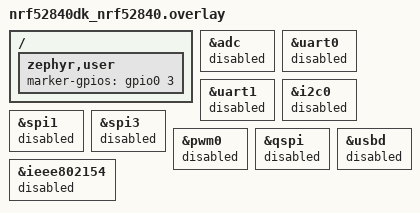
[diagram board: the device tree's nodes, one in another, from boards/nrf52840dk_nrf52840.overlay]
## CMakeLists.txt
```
cmake_minimum_required(VERSION 3.20.0)
find_package(Zephyr REQUIRED HINTS $ENV{ZEPHYR_BASE})
project(low_power_zephyr_comparison)

target_sources(app PRIVATE
    src/main.c
    ../common/src/scenario.c
)
target_include_directories(app PRIVATE ../common/include)

target_compile_definitions(app PRIVATE
    SCENARIO_PERIOD_MS=${CONFIG_SCENARIO_PERIOD_MS}
    SCENARIO_PULSE_MS=${CONFIG_SCENARIO_PULSE_MS}
    SCENARIO_WORKLOAD_ITERATIONS=${CONFIG_SCENARIO_WORKLOAD_ITERATIONS}
)
```

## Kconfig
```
mainmenu "Low-Power nRF52 Comparison"

config SCENARIO_LED
    bool "Use the on-board LED as a 50 ms activity indicator"
    default y
    help
      The on-board LED adds a noticeable load to current measurements.
      Disable it for an MCU-focused low-power baseline. Keep the same
      setting in both the bare-metal and Zephyr builds.

config SCENARIO_PERIOD_MS
    int "Periodic wake-up interval in milliseconds"
    range 100 600000
    default 5000
    help
      Period between application wake-up events.

config SCENARIO_PULSE_MS
    int "LED pulse duration in milliseconds"
    range 1 999
    default 50
    help
      LED on-time. Must be shorter than the periodic interval.

config SCENARIO_WORKLOAD_ITERATIONS
    int "Deterministic workload iterations"
    range 1 1000000
    default 4096
    help
      Number of iterations executed on each wake-up, shared with the
      bare-metal build through common/scenario.c.
```

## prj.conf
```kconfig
# System power management. On nRF52832, the idle thread waits for events
# (System ON idle); no explicit System OFF transition is requested.
CONFIG_PM=y
CONFIG_TICKLESS_KERNEL=y

# GPIO application; no serial console/logging during power measurements.
CONFIG_GPIO=y
CONFIG_SERIAL=n
CONFIG_CONSOLE=n
CONFIG_UART_CONSOLE=n
CONFIG_PRINTK=n
CONFIG_LOG=n

# Keep the benchmark small and deterministic.
CONFIG_MAIN_STACK_SIZE=1024
CONFIG_ASSERT=y
CONFIG_SCENARIO_LED=y
CONFIG_SCENARIO_PERIOD_MS=5000
CONFIG_SCENARIO_PULSE_MS=50
CONFIG_SCENARIO_WORKLOAD_ITERATIONS=4096
```

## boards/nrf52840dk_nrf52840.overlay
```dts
/* nRF52840 DK, PCA10056. The board DTS exposes LED1 as DT_ALIAS(led0)
 * on P0.13 (active-low). P0.03 is Arduino A0 and is the timing marker.
 */
#include <zephyr/dt-bindings/gpio/gpio.h>

/ {
    zephyr,user {
        marker-gpios = <&gpio0 3 GPIO_ACTIVE_HIGH>;
    };
};

/* The workload only needs GPIO and the Zephyr system clock. Disable unused
 * board peripherals so their drivers/pins do not pollute the current baseline. */
&adc {
    status = "disabled";
};
&uart0 {
    status = "disabled";
};
&uart1 {
    status = "disabled";
};
&i2c0 {
    status = "disabled";
};
&spi1 {
    status = "disabled";
};
&spi3 {
    status = "disabled";
};
&pwm0 {
    status = "disabled";
};
&qspi {
    status = "disabled";
};
&ieee802154 {
    status = "disabled";
};
&usbd {
    status = "disabled";
};
```

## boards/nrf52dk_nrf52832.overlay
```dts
/* PCA10040 nRF52 DK (nRF52832). LED1 = P0.17 (led0 alias),
 * BUTTON1 = P0.13 (sw0 alias), marker = P0.03 (Arduino A0).
 * Avoid referencing peripherals not present in this SoC's DTS.
 */
#include <zephyr/dt-bindings/gpio/gpio.h>

/ {
    zephyr,user {
        marker-gpios = <&gpio0 3 GPIO_ACTIVE_HIGH>;
    };
};

&uart0 { status = "disabled"; };
```

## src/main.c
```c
#include <errno.h>
#include <zephyr/device.h>
#include <zephyr/devicetree.h>
#include <zephyr/drivers/gpio.h>
#include <zephyr/kernel.h>
#include <zephyr/sys/util.h>

#include "scenario.h"

#if CONFIG_SCENARIO_PULSE_MS >= CONFIG_SCENARIO_PERIOD_MS
#error "SCENARIO_PULSE_MS must be shorter than SCENARIO_PERIOD_MS"
#endif

#define MARKER_NODE DT_PATH(zephyr_user)
static const struct gpio_dt_spec marker_gpio =
    GPIO_DT_SPEC_GET(MARKER_NODE, marker_gpios);

#if CONFIG_SCENARIO_LED
static const struct gpio_dt_spec led_gpio =
    GPIO_DT_SPEC_GET(DT_ALIAS(led0), gpios);
#endif

K_SEM_DEFINE(wake_sem, 0, 1);

static void periodic_timer_expiry(struct k_timer *timer)
{
    ARG_UNUSED(timer);
    /* k_sem_give() is ISR-safe; the application work runs in main context. */
    k_sem_give(&wake_sem);
}

K_TIMER_DEFINE(periodic_timer, periodic_timer_expiry, NULL);

int main(void)
{
    int ret;

    if (!device_is_ready(marker_gpio.port)) {
        return -ENODEV;
    }

    ret = gpio_pin_configure_dt(&marker_gpio, GPIO_OUTPUT_INACTIVE);
    if (ret < 0) {
        return ret;
    }

#if CONFIG_SCENARIO_LED
    if (!device_is_ready(led_gpio.port)) {
        return -ENODEV;
    }

    ret = gpio_pin_configure_dt(&led_gpio, GPIO_OUTPUT_INACTIVE);
    if (ret < 0) {
        return ret;
    }
#endif

    k_timer_start(&periodic_timer,
                  K_MSEC(CONFIG_SCENARIO_PERIOD_MS),
                  K_MSEC(CONFIG_SCENARIO_PERIOD_MS));

    for (;;) {
        /* With no runnable application thread, Zephyr's idle thread can
         * enter the SoC's System ON idle state and wait for the next event. */
        k_sem_take(&wake_sem, K_FOREVER);

#if CONFIG_SCENARIO_LED
        (void)gpio_pin_set_dt(&led_gpio, 1); /* Logical active = LED on. */
#endif

        (void)gpio_pin_set_dt(&marker_gpio, 1);
        (void)scenario_run_workload();
        (void)gpio_pin_set_dt(&marker_gpio, 0);

        /* The main thread sleeps during the remainder of the visible pulse.
         * This is intentionally not a busy-wait. */
        k_sleep(K_MSEC(CONFIG_SCENARIO_PULSE_MS));

#if CONFIG_SCENARIO_LED
        (void)gpio_pin_set_dt(&led_gpio, 0);
#endif
    }

    return 0;
}
```
